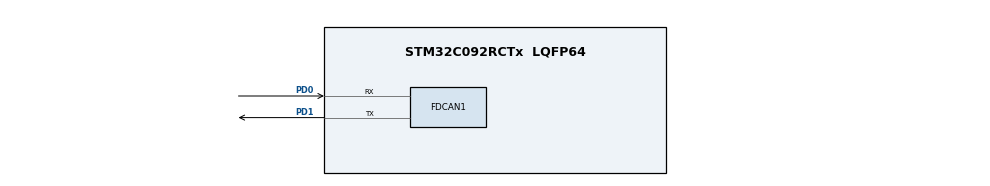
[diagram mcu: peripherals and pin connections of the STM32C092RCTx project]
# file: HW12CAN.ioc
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FDCAN1.AutoRetransmission=ENABLE
FDCAN1.CalculateBaudRateData=250000
FDCAN1.CalculateBaudRateNominal=250000
FDCAN1.CalculateTimeBitNominal=4000
FDCAN1.CalculateTimeQuantumNominal=250
FDCAN1.DataPrescaler=12
FDCAN1.DataSyncJumpWidth=2
FDCAN1.DataTimeSeg1=13
FDCAN1.DataTimeSeg2=2
FDCAN1.FrameFormat=FDCAN_FRAME_CLASSIC
FDCAN1.NominalPrescaler=12
FDCAN1.NominalSyncJumpWidth=2
FDCAN1.NominalTimeSeg1=13
FDCAN1.NominalTimeSeg2=2
FDCAN1.StdFiltersNbr=1
FDCAN1.TransmitPause=DISABLE
Mcu.Family=STM32C0
Mcu.Name=STM32C092RCTx
Mcu.Package=LQFP64
NUCLEO-C092RC.BUTTON=1
NUCLEO-C092RC.Bsp_Common_DEMO=true
NUCLEO-C092RC.LD1=true
NUCLEO-C092RC.LD2=true
NUCLEO-C092RC.VCP=true
NVIC.EXTI4_15_IRQn=true\:0\:0\:false\:false\:true\:false\:true\:true
PA13.GPIO_Label=SWDIO
PA13.Signal=DEBUG_SWDIO
PA14-BOOT0.GPIO_Label=SWCLK
PA14-BOOT0.Signal=DEBUG_SWCLK
PA2.Signal=USART2_TX
PA3.Signal=USART2_RX
PC14-OSCX_IN(PC14).GPIO_Label=OSCX_IN
PC14-OSCX_IN(PC14).Signal=RCC_OSCX_IN
PC15-OSCX_OUT(PC15).GPIO_Label=OSCX_OUT
PC15-OSCX_OUT(PC15).Signal=RCC_OSCX_OUT
PD0.Mode=FDCAN_Activate
PD0.Signal=FDCAN1_RX
PD1.Mode=FDCAN_Activate
PD1.Signal=FDCAN1_TX
PF0-OSC_IN(PF0).GPIO_Label=OSC_IN
PF0-OSC_IN(PF0).Signal=RCC_OSC_IN
PF1-OSC_OUT(PF1).GPIO_Label=OSC_OUT
PF1-OSC_OUT(PF1).Signal=RCC_OSC_OUT
ProjectManager.HeapSize=0x200
ProjectManager.StackSize=0x400
ProjectManager.TargetToolchain=STM32CubeIDE
RCC.ADCFreq_Value=48000000
RCC.AHBFreq_Value=48000000
RCC.CortexFreq_Value=48000000
RCC.EXTERNAL_CLOCK_VALUE=12288000
RCC.HCLKFreq_Value=48000000
RCC.HSE_VALUE=8000000
RCC.HSI_VALUE=48000000
RCC.HSISYSCLKDivider=RCC_HSI_DIV1
RCC.LSE_VALUE=32768
RCC.SYSCLKFreq_VALUE=48000000
VP_NUCLEO-C092RC_VS_BSP_COMMON.Mode=COMMON
board=NUCLEO-C092RC

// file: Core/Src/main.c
/* USER CODE BEGIN Header */
/**
  ******************************************************************************
  * @file           : main.c
  * @brief          : Main program body
  ******************************************************************************
  * @attention
  *
  * Copyright (c) 2026 STMicroelectronics.
  * All rights reserved.
  *
  * This software is licensed under terms that can be found in the LICENSE file
  * in the root directory of this software component.
  * If no LICENSE file comes with this software, it is provided AS-IS.
  *
  ******************************************************************************
  */
/* USER CODE END Header */
#include "main.h"

COM_InitTypeDef BspCOMInit;
__IO uint32_t BspButtonState = BUTTON_RELEASED;

FDCAN_HandleTypeDef hfdcan1;

/* USER CODE BEGIN PV */
static uint8_t CanTxData[8] = {'B', '1', ' ', 'p', 'r', 'e', 's', 's'};

/* USER CODE END PV */

void SystemClock_Config(void);
static void MX_GPIO_Init(void);
static void MX_FDCAN1_Init(void);
/* USER CODE BEGIN PFP */
static void CAN_User_Init(void);
static void CAN_Send_Button_Message(void);
static void CAN_Poll_Rx(void);
static uint8_t CAN_DlcToBytes(uint32_t dlc);
static void CAN_Print_Status(const char *prefix);
static void CAN_Recover_If_BusOff(void);

/* USER CODE END PFP */

int main(void)
{

  /* MCU Configuration--------------------------------------------------------*/

  /* Reset of all peripherals, Initializes the Flash interface and the Systick. */
  HAL_Init();

  /* Configure the system clock */
  SystemClock_Config();

  /* Initialize all configured peripherals */
  MX_GPIO_Init();
  MX_FDCAN1_Init();

  /* Initialize leds */
  BSP_LED_Init(LED_GREEN);
  BSP_LED_Init(LED_BLUE);

  /* Initialize USER push-button, will be used to trigger an interrupt each time it's pressed.*/
  BSP_PB_Init(BUTTON_USER, BUTTON_MODE_EXTI);

  /* Initialize COM1 port (115200, 8 bits (7-bit data + 1 stop bit), no parity */
  BspCOMInit.BaudRate   = 115200;
  BspCOMInit.WordLength = COM_WORDLENGTH_8B;
  BspCOMInit.StopBits   = COM_STOPBITS_1;
  BspCOMInit.Parity     = COM_PARITY_NONE;
  BspCOMInit.HwFlowCtl  = COM_HWCONTROL_NONE;
  if (BSP_COM_Init(COM1, &BspCOMInit) != BSP_ERROR_NONE)
  {
    Error_Handler();
  }

  /* USER CODE BEGIN BSP */
  CAN_User_Init();

  /* -- Sample board code to send message over COM1 port ---- */
  printf("Classic CAN demo ready. Press B1 to send CAN ID 0x111.\n\r");

  /* -- Sample board code to switch on leds ---- */
  BSP_LED_On(LED_GREEN);
  BSP_LED_On(LED_BLUE);

  /* USER CODE END BSP */

  /* Infinite loop */
  /* USER CODE BEGIN WHILE */
  while (1)
  {

    /* -- Sample board code for User push-button in interrupt mode ---- */
    if (BspButtonState == BUTTON_PRESSED)
    {
      /* Update button state */
      BspButtonState = BUTTON_RELEASED;
      /* -- Sample board code to toggle leds ---- */
      BSP_LED_Toggle(LED_GREEN);
      BSP_LED_Toggle(LED_BLUE);

      /* ..... Perform your action ..... */
      CAN_Send_Button_Message();
    }
    /* USER CODE END WHILE */

    /* USER CODE BEGIN 3 */
    CAN_Poll_Rx();
  }
  /* USER CODE END 3 */
}

void SystemClock_Config(void)
{
  RCC_OscInitTypeDef RCC_OscInitStruct = {0};
  RCC_ClkInitTypeDef RCC_ClkInitStruct = {0};

  __HAL_FLASH_SET_LATENCY(FLASH_LATENCY_1);

  /** Initializes the RCC Oscillators according to the specified parameters
  * in the RCC_OscInitTypeDef structure.
  */
  RCC_OscInitStruct.OscillatorType = RCC_OSCILLATORTYPE_HSI;
  RCC_OscInitStruct.HSIState = RCC_HSI_ON;
  RCC_OscInitStruct.HSIDiv = RCC_HSI_DIV1;
  RCC_OscInitStruct.HSICalibrationValue = RCC_HSICALIBRATION_DEFAULT;
  if (HAL_RCC_OscConfig(&RCC_OscInitStruct) != HAL_OK)
  {
    Error_Handler();
  }

  /** Initializes the CPU, AHB and APB buses clocks
  */
  RCC_ClkInitStruct.ClockType = RCC_CLOCKTYPE_HCLK|RCC_CLOCKTYPE_SYSCLK
                              |RCC_CLOCKTYPE_PCLK1;
  RCC_ClkInitStruct.SYSCLKSource = RCC_SYSCLKSOURCE_HSI;
  RCC_ClkInitStruct.SYSCLKDivider = RCC_SYSCLK_DIV1;
  RCC_ClkInitStruct.AHBCLKDivider = RCC_HCLK_DIV1;
  RCC_ClkInitStruct.APB1CLKDivider = RCC_APB1_DIV1;

  if (HAL_RCC_ClockConfig(&RCC_ClkInitStruct, FLASH_LATENCY_1) != HAL_OK)
  {
    Error_Handler();
  }
}

static void MX_FDCAN1_Init(void)
{

  hfdcan1.Instance = FDCAN1;
  hfdcan1.Init.ClockDivider = FDCAN_CLOCK_DIV1;
  hfdcan1.Init.FrameFormat = FDCAN_FRAME_CLASSIC;
  hfdcan1.Init.Mode = FDCAN_MODE_NORMAL;
  hfdcan1.Init.AutoRetransmission = ENABLE;
  hfdcan1.Init.TransmitPause = DISABLE;
  hfdcan1.Init.ProtocolException = DISABLE;
  hfdcan1.Init.NominalPrescaler = 12;
  hfdcan1.Init.NominalSyncJumpWidth = 2;
  hfdcan1.Init.NominalTimeSeg1 = 13;
  hfdcan1.Init.NominalTimeSeg2 = 2;
  hfdcan1.Init.DataPrescaler = 12;
  hfdcan1.Init.DataSyncJumpWidth = 2;
  hfdcan1.Init.DataTimeSeg1 = 13;
  hfdcan1.Init.DataTimeSeg2 = 2;
  hfdcan1.Init.StdFiltersNbr = 1;
  hfdcan1.Init.ExtFiltersNbr = 0;
  hfdcan1.Init.TxFifoQueueMode = FDCAN_TX_FIFO_OPERATION;
  if (HAL_FDCAN_Init(&hfdcan1) != HAL_OK)
  {
    Error_Handler();
  }

}

static void MX_GPIO_Init(void)
{

  /* GPIO Ports Clock Enable */
  __HAL_RCC_GPIOC_CLK_ENABLE();
  __HAL_RCC_GPIOF_CLK_ENABLE();
  __HAL_RCC_GPIOA_CLK_ENABLE();

}

/* USER CODE BEGIN 4 */
static void CAN_User_Init(void)
{
  FDCAN_FilterTypeDef sFilterConfig = {0};

  sFilterConfig.IdType = FDCAN_STANDARD_ID;
  sFilterConfig.FilterIndex = 0;
  sFilterConfig.FilterType = FDCAN_FILTER_MASK;
  sFilterConfig.FilterConfig = FDCAN_FILTER_TO_RXFIFO0;
  sFilterConfig.FilterID1 = 0x000;
  sFilterConfig.FilterID2 = 0x000;

  if (HAL_FDCAN_ConfigFilter(&hfdcan1, &sFilterConfig) != HAL_OK)
  {
    Error_Handler();
  }

  if (HAL_FDCAN_ConfigGlobalFilter(&hfdcan1,
                                   FDCAN_ACCEPT_IN_RX_FIFO0,
                                   FDCAN_ACCEPT_IN_RX_FIFO0,
                                   FDCAN_REJECT_REMOTE,
                                   FDCAN_REJECT_REMOTE) != HAL_OK)
  {
    Error_Handler();
  }

  if (HAL_FDCAN_Start(&hfdcan1) != HAL_OK)
  {
    Error_Handler();
  }

  CAN_Print_Status("CAN start");
}

static void CAN_Send_Button_Message(void)
{
  FDCAN_TxHeaderTypeDef TxHeader = {0};

  CAN_Recover_If_BusOff();

  TxHeader.Identifier = 0x111;
  TxHeader.IdType = FDCAN_STANDARD_ID;
  TxHeader.TxFrameType = FDCAN_DATA_FRAME;
  TxHeader.DataLength = FDCAN_DLC_BYTES_8;
  TxHeader.ErrorStateIndicator = FDCAN_ESI_ACTIVE;
  TxHeader.BitRateSwitch = FDCAN_BRS_OFF;
  TxHeader.FDFormat = FDCAN_CLASSIC_CAN;
  TxHeader.TxEventFifoControl = FDCAN_NO_TX_EVENTS;
  TxHeader.MessageMarker = 0;

  if (HAL_FDCAN_AddMessageToTxFifoQ(&hfdcan1, &TxHeader, CanTxData) == HAL_OK)
  {
    printf("TX queued CAN ID 0x%03lX:", (unsigned long)TxHeader.Identifier);
    for (uint8_t i = 0; i < 8; i++)
    {
      printf(" %02X", CanTxData[i]);
    }
    printf("\n\r");
    HAL_Delay(2);
    CAN_Print_Status("After TX");
  }
  else
  {
    printf("CAN TX failed\n\r");
    CAN_Print_Status("TX add failed");
  }
}

static void CAN_Poll_Rx(void)
{
  FDCAN_RxHeaderTypeDef RxHeader = {0};
  uint8_t RxData[64] = {0};

  while (HAL_FDCAN_GetRxFifoFillLevel(&hfdcan1, FDCAN_RX_FIFO0) > 0U)
  {
    if (HAL_FDCAN_GetRxMessage(&hfdcan1, FDCAN_RX_FIFO0, &RxHeader, RxData) == HAL_OK)
    {
      uint8_t len = CAN_DlcToBytes(RxHeader.DataLength);

      if (RxHeader.IdType == FDCAN_STANDARD_ID)
      {
        printf("RX CAN ID 0x%03lX:", (unsigned long)RxHeader.Identifier);
      }
      else
      {
        printf("RX CAN ID 0x%08lX:", (unsigned long)RxHeader.Identifier);
      }
      for (uint8_t i = 0; i < len; i++)
      {
        printf(" %02X", RxData[i]);
      }
      printf("\n\r");
    }
  }
}

static uint8_t CAN_DlcToBytes(uint32_t dlc)
{
  switch (dlc)
  {
    case FDCAN_DLC_BYTES_0:
      return 0;
    case FDCAN_DLC_BYTES_1:
      return 1;
    case FDCAN_DLC_BYTES_2:
      return 2;
    case FDCAN_DLC_BYTES_3:
      return 3;
    case FDCAN_DLC_BYTES_4:
      return 4;
    case FDCAN_DLC_BYTES_5:
      return 5;
    case FDCAN_DLC_BYTES_6:
      return 6;
    case FDCAN_DLC_BYTES_7:
      return 7;
    case FDCAN_DLC_BYTES_8:
      return 8;
    case FDCAN_DLC_BYTES_12:
      return 12;
    case FDCAN_DLC_BYTES_16:
      return 16;
    case FDCAN_DLC_BYTES_20:
      return 20;
    case FDCAN_DLC_BYTES_24:
      return 24;
    case FDCAN_DLC_BYTES_32:
      return 32;
    case FDCAN_DLC_BYTES_48:
      return 48;
    case FDCAN_DLC_BYTES_64:
      return 64;
    default:
      return 8;
  }
}

static void CAN_Print_Status(const char *prefix)
{
  FDCAN_ProtocolStatusTypeDef status = {0};
  FDCAN_ErrorCountersTypeDef counters = {0};

  if ((HAL_FDCAN_GetProtocolStatus(&hfdcan1, &status) == HAL_OK) &&
      (HAL_FDCAN_GetErrorCounters(&hfdcan1, &counters) == HAL_OK))
  {
    printf("%s: LEC=%lu ACT=%lu EW=%lu EP=%lu BO=%lu REC=%lu TEC=%lu TXfree=%lu\n\r",
           prefix,
           (unsigned long)status.LastErrorCode,
           (unsigned long)status.Activity,
           (unsigned long)status.Warning,
           (unsigned long)status.ErrorPassive,
           (unsigned long)status.BusOff,
           (unsigned long)counters.RxErrorCnt,
           (unsigned long)counters.TxErrorCnt,
           (unsigned long)HAL_FDCAN_GetTxFifoFreeLevel(&hfdcan1));
  }
}

static void CAN_Recover_If_BusOff(void)
{
  FDCAN_ProtocolStatusTypeDef status = {0};

  if ((HAL_FDCAN_GetProtocolStatus(&hfdcan1, &status) == HAL_OK) &&
      (status.BusOff != 0U))
  {
    printf("CAN bus-off, restarting FDCAN\n\r");
    (void)HAL_FDCAN_AbortTxRequest(&hfdcan1,
                                   FDCAN_TX_BUFFER0 | FDCAN_TX_BUFFER1 | FDCAN_TX_BUFFER2);
    (void)HAL_FDCAN_Stop(&hfdcan1);
    if (HAL_FDCAN_Start(&hfdcan1) != HAL_OK)
    {
      Error_Handler();
    }
    CAN_Print_Status("After restart");
  }
}

/* USER CODE END 4 */

/**
  * @brief  BSP Push Button callback
  * @param  Button Specifies the pressed button
  * @retval None
  */
void BSP_PB_Callback(Button_TypeDef Button)
{
  if (Button == BUTTON_USER)
  {
    BspButtonState = BUTTON_PRESSED;
  }
}

void Error_Handler(void)
{
  __disable_irq();
  while (1)
  {
  }
}
